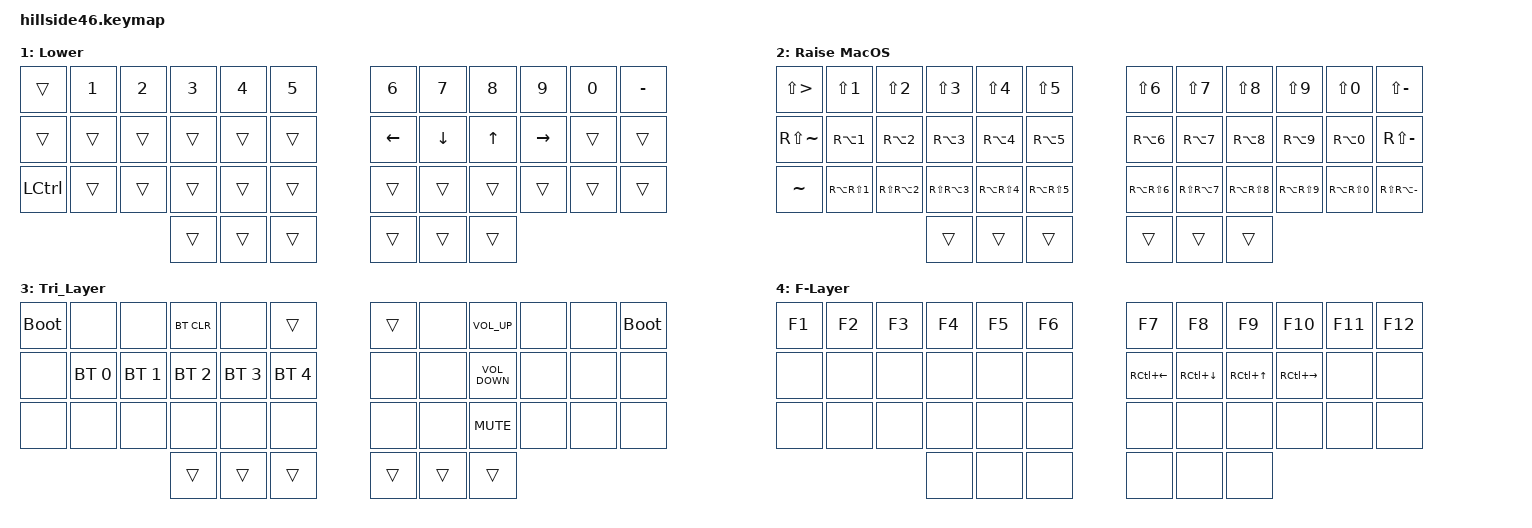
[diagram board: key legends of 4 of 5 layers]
/*
 * Copyright (c) 2020 The ZMK Contributors
 *
 * SPDX-License-Identifier: MIT
 */

#include <behaviors.dtsi>
#include <dt-bindings/zmk/bt.h>
#include <dt-bindings/zmk/keys.h>

/ {
    combos {
        compatible = "zmk,combos";

        f_layer_l {
            bindings = <&mo 4>;
            key-positions = <37 38>;
        };

        f_layer_r {
            bindings = <&mo 4>;
            key-positions = <39 40>;
        };

        copy_mac {
            bindings = <&kp RG(C)>;
            key-positions = <26 27>;
            layers = <0>;
        };

        paste_mac {
            bindings = <&kp LG(V)>;
            key-positions = <28 27>;
            layers = <0>;
        };

        cut_mac {
            bindings = <&kp LG(X)>;
            key-positions = <26 28>;
        };

        undo_mac {
            bindings = <&kp LG(Z)>;
            key-positions = <25 26>;
        };

        bcksp {
            bindings = <&kp BACKSPACE>;
            key-positions = <8 7>;
        };

        del {
            bindings = <&kp DEL>;
            key-positions = <8 9>;
        };
    };

    behaviors {
        HRML: HRML {
            compatible = "zmk,behavior-hold-tap";
            label = "HRML";
            bindings = <&kp>, <&kp>;

            #binding-cells = <2>;
            tapping-term-ms = <280>;
            require-prior-idle-ms = <150>;
            quick-tap-ms = <175>;
            hold-trigger-key-positions = <13 14 15 16>;
            flavor = "balanced";
            hold-trigger-on-release;
        };

        HRMR: HRMR {
            compatible = "zmk,behavior-hold-tap";
            label = "HRMR";
            bindings = <&kp>, <&kp>;

            #binding-cells = <2>;
            tapping-term-ms = <280>;
            quick-tap-ms = <175>;
            require-prior-idle-ms = <150>;
            hold-trigger-key-positions = <19 20 21 22>;
            flavor = "balanced";
            hold-trigger-on-release;
        };

        bspc_del: bspc_del {
            compatible = "zmk,behavior-mod-morph";
            label = "BSPC_DEL";
            bindings = <&kp BACKSPACE>, <&kp DEL>;

            #binding-cells = <0>;
            mods = <(MOD_LSFT|MOD_RSFT)>;
            keep-mods = <(MOD_LSFT|MOD_RSFT)>;
        };

        mod_dance: mod_dance {
            compatible = "zmk,behavior-tap-dance";
            label = "MOD_DANCE";
            #binding-cells = <0>;
            bindings = <&kp LGUI>, <&kp LCTRL>;

            tapping-term-ms = <500>;
        };
    };

    keymap {
        compatible = "zmk,keymap";

        MacOS {
            display-name = "MACOS";
            bindings = <
&kp TAB     &kp Q  &kp W  &kp E       &kp R      &kp T    &kp Y  &kp U      &kp I      &kp O    &kp P             &bspc_del
&kp LSHIFT  &kp A  &kp S  &kp D       &kp F      &kp G    &kp H  &kp J      &kp K      &kp L    &HRMR RSHFT SEMI  &kp SQT
&bspc_del   &kp Z  &kp X  &kp C       &kp V      &kp B    &kp N  &kp M      &kp COMMA  &kp DOT  &kp FSLH          &kp ESC
                    &kp A &kp B &mod_dance  &kp SPACE  &mo 1    &mo 2  &kp ENTER  &kp RALT &kp C &kp D
            >;
        };

        lower_layer {
            // -----------------------------------------------------------------------------------------
            // |  TAB |  1  |  2  |  3  |  4  |  5  |   |  6  |  7  |  8  |  9  |  0  | BKSP |
            // | BTCLR| BT1 | BT2 | BT3 | BT4 | BT5 |   | LFT | DWN |  UP | RGT |     |      |
            // | SHFT |     |     |     |     |     |   |     |     |     |     |     |      |
            //                    | GUI |     | SPC |   | ENT |     | ALT |

            display-name = "Lower";
            bindings = <
&trans     &kp N1  &kp N2  &kp N3  &kp N4  &kp N5    &kp N6    &kp N7    &kp N8  &kp N9     &kp N0  &kp MINUS
&trans     &trans  &trans  &trans  &trans  &trans    &kp LEFT  &kp DOWN  &kp UP  &kp RIGHT  &trans  &trans
&kp LCTRL  &trans  &trans  &trans  &trans  &trans    &trans    &trans    &trans  &trans     &trans  &trans
                           &trans  &trans  &trans    &trans    &trans    &trans
            >;
        };

        raise_macOS {
            display-name = "Raise MacOS";
            bindings = <
&kp LS(GT)     &kp LS(NUMBER_1)      &kp LS(NUMBER_2)      &kp LS(NUMBER_3)  &kp LS(NUMBER_4)  &kp LS(N5)        &kp LS(NUMBER_6)  &kp LS(N7)      &kp LS(N8)      &kp LS(N9)      &kp LS(N0)      &kp LS(MINUS)
&kp RS(TILDE)  &kp RA(NUMBER_1)      &kp RA(NUMBER_2)      &kp RA(NUMBER_3)  &kp RA(NUMBER_4)  &kp RA(N5)        &kp RA(NUMBER_6)  &kp RA(N7)      &kp RA(N8)      &kp RA(N9)      &kp RA(N0)      &kp RS(MINUS)
&kp TILDE      &kp RA(RS(NUMBER_1))  &kp RS(RA(NUMBER_2))  &kp RS(RA(N3))    &kp RA(RS(N4))    &kp RA(RS(N5))    &kp RA(RS(N6))    &kp RS(RA(N7))  &kp RA(RS(N8))  &kp RA(RS(N9))  &kp RA(RS(N0))  &kp RS(RA(MINUS))
                                                           &trans            &trans            &trans            &trans            &trans          &trans
            >;
        };

        tri_layer {
            bindings = <
&bootloader  &none         &none         &bt BT_CLR    &none         &trans          &trans  &none   &kp C_VOLUME_UP    &none  &none  &bootloader
&none        &bt BT_SEL 0  &bt BT_SEL 1  &bt BT_SEL 2  &bt BT_SEL 3  &bt BT_SEL 4    &none   &none   &kp C_VOLUME_DOWN  &none  &none  &none
&none        &none         &none         &none         &none         &none           &none   &none   &kp K_MUTE         &none  &none  &none
                                         &trans        &trans        &trans          &trans  &trans  &trans
            >;

            label = "Tri_Layer";
        };

        F_layer {
            bindings = <
&kp F1  &kp F2  &kp F3  &kp F4  &kp F5  &kp F6    &kp F7              &kp F8        &kp F9            &kp F10        &kp F11  &kp F12
&none   &none   &none   &none   &none   &none     &kp RC(LEFT_ARROW)  &kp RC(DOWN)  &kp RC(UP_ARROW)  &kp RC(RIGHT)  &none    &none
&none   &none   &none   &none   &none   &none     &none               &none         &none             &none          &none    &none
                        &none   &none   &none     &none               &none         &none
            >;

            label = "F-Layer";
        };
    };

    conditional_layers {
        compatible = "zmk,conditional-layers";

        tri_MAC {
            if-layers = <1 2>;
            then-layer = <3>;
        };
    };
};
